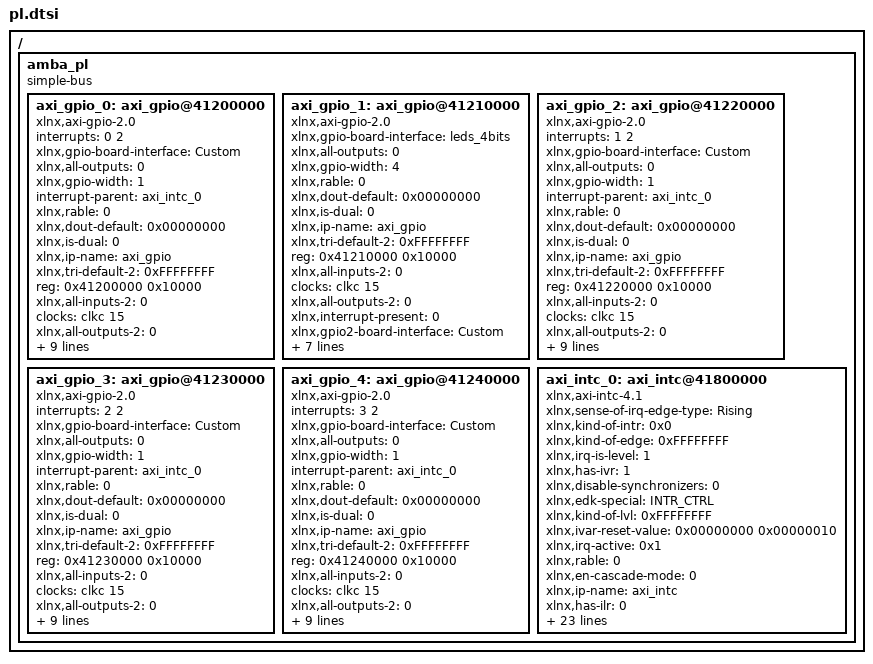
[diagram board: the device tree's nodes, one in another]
/ {
	amba_pl: amba_pl {
		ranges;
		compatible = "simple-bus";
		#address-cells = <1>;
		#size-cells = <1>;
		axi_gpio_0: axi_gpio@41200000 {
			#interrupt-cells = <2>;
			interrupts = < 0 2 >;
			xlnx,gpio-board-interface = "Custom";
			compatible = "xlnx,axi-gpio-2.0" , "xlnx,xps-gpio-1.00.a";
			xlnx,all-outputs = <0>;
			xlnx,gpio-width = <1>;
			interrupt-parent = <&axi_intc_0>;
			xlnx,rable = <0>;
			xlnx,dout-default = <0x00000000>;
			xlnx,is-dual = <0>;
			xlnx,ip-name = "axi_gpio";
			xlnx,tri-default-2 = <0xFFFFFFFF>;
			reg = <0x41200000 0x10000>;
			xlnx,all-inputs-2 = <0>;
			clocks = <&clkc 15>;
			xlnx,all-outputs-2 = <0>;
			xlnx,interrupt-present = <1>;
			xlnx,gpio2-board-interface = "Custom";
			xlnx,edk-iptype = "PERIPHERAL";
			xlnx,dout-default-2 = <0x00000000>;
			xlnx,gpio2-width = <32>;
			status = "okay";
			clock-names = "s_axi_aclk";
			interrupt-controller;
			interrupt-names = "ip2intc_irpt";
			xlnx,tri-default = <0xFFFFFFFF>;
			xlnx,name = "axi_gpio_0";
			xlnx,all-inputs = <1>;
		};
		axi_gpio_1: axi_gpio@41210000 {
			xlnx,gpio-board-interface = "leds_4bits";
			compatible = "xlnx,axi-gpio-2.0" , "xlnx,xps-gpio-1.00.a";
			xlnx,all-outputs = <0>;
			xlnx,gpio-width = <4>;
			xlnx,rable = <0>;
			xlnx,dout-default = <0x00000000>;
			xlnx,is-dual = <0>;
			xlnx,ip-name = "axi_gpio";
			xlnx,tri-default-2 = <0xFFFFFFFF>;
			reg = <0x41210000 0x10000>;
			xlnx,all-inputs-2 = <0>;
			clocks = <&clkc 15>;
			xlnx,all-outputs-2 = <0>;
			xlnx,interrupt-present = <0>;
			xlnx,gpio2-board-interface = "Custom";
			xlnx,edk-iptype = "PERIPHERAL";
			xlnx,dout-default-2 = <0x00000000>;
			xlnx,gpio2-width = <32>;
			status = "okay";
			clock-names = "s_axi_aclk";
			xlnx,use-board-flow;
			xlnx,tri-default = <0xFFFFFFFF>;
			xlnx,name = "axi_gpio_1";
			xlnx,all-inputs = <0>;
		};
		axi_gpio_2: axi_gpio@41220000 {
			#interrupt-cells = <2>;
			interrupts = < 1 2 >;
			xlnx,gpio-board-interface = "Custom";
			compatible = "xlnx,axi-gpio-2.0" , "xlnx,xps-gpio-1.00.a";
			xlnx,all-outputs = <0>;
			xlnx,gpio-width = <1>;
			interrupt-parent = <&axi_intc_0>;
			xlnx,rable = <0>;
			xlnx,dout-default = <0x00000000>;
			xlnx,is-dual = <0>;
			xlnx,ip-name = "axi_gpio";
			xlnx,tri-default-2 = <0xFFFFFFFF>;
			reg = <0x41220000 0x10000>;
			xlnx,all-inputs-2 = <0>;
			clocks = <&clkc 15>;
			xlnx,all-outputs-2 = <0>;
			xlnx,interrupt-present = <1>;
			xlnx,gpio2-board-interface = "Custom";
			xlnx,edk-iptype = "PERIPHERAL";
			xlnx,dout-default-2 = <0x00000000>;
			xlnx,gpio2-width = <32>;
			status = "okay";
			clock-names = "s_axi_aclk";
			interrupt-controller;
			interrupt-names = "ip2intc_irpt";
			xlnx,tri-default = <0xFFFFFFFF>;
			xlnx,name = "axi_gpio_2";
			xlnx,all-inputs = <1>;
		};
		axi_gpio_3: axi_gpio@41230000 {
			#interrupt-cells = <2>;
			interrupts = < 2 2 >;
			xlnx,gpio-board-interface = "Custom";
			compatible = "xlnx,axi-gpio-2.0" , "xlnx,xps-gpio-1.00.a";
			xlnx,all-outputs = <0>;
			xlnx,gpio-width = <1>;
			interrupt-parent = <&axi_intc_0>;
			xlnx,rable = <0>;
			xlnx,dout-default = <0x00000000>;
			xlnx,is-dual = <0>;
			xlnx,ip-name = "axi_gpio";
			xlnx,tri-default-2 = <0xFFFFFFFF>;
			reg = <0x41230000 0x10000>;
			xlnx,all-inputs-2 = <0>;
			clocks = <&clkc 15>;
			xlnx,all-outputs-2 = <0>;
			xlnx,interrupt-present = <1>;
			xlnx,gpio2-board-interface = "Custom";
			xlnx,edk-iptype = "PERIPHERAL";
			xlnx,dout-default-2 = <0x00000000>;
			xlnx,gpio2-width = <32>;
			status = "okay";
			clock-names = "s_axi_aclk";
			interrupt-controller;
			interrupt-names = "ip2intc_irpt";
			xlnx,tri-default = <0xFFFFFFFF>;
			xlnx,name = "axi_gpio_3";
			xlnx,all-inputs = <1>;
		};
		axi_gpio_4: axi_gpio@41240000 {
			#interrupt-cells = <2>;
			interrupts = < 3 2 >;
			xlnx,gpio-board-interface = "Custom";
			compatible = "xlnx,axi-gpio-2.0" , "xlnx,xps-gpio-1.00.a";
			xlnx,all-outputs = <0>;
			xlnx,gpio-width = <1>;
			interrupt-parent = <&axi_intc_0>;
			xlnx,rable = <0>;
			xlnx,dout-default = <0x00000000>;
			xlnx,is-dual = <0>;
			xlnx,ip-name = "axi_gpio";
			xlnx,tri-default-2 = <0xFFFFFFFF>;
			reg = <0x41240000 0x10000>;
			xlnx,all-inputs-2 = <0>;
			clocks = <&clkc 15>;
			xlnx,all-outputs-2 = <0>;
			xlnx,interrupt-present = <1>;
			xlnx,gpio2-board-interface = "Custom";
			xlnx,edk-iptype = "PERIPHERAL";
			xlnx,dout-default-2 = <0x00000000>;
			xlnx,gpio2-width = <32>;
			status = "okay";
			clock-names = "s_axi_aclk";
			interrupt-controller;
			interrupt-names = "ip2intc_irpt";
			xlnx,tri-default = <0xFFFFFFFF>;
			xlnx,name = "axi_gpio_4";
			xlnx,all-inputs = <1>;
		};
		axi_intc_0: axi_intc@41800000 {
			#interrupt-cells = <2>;
			xlnx,sense-of-irq-edge-type = "Rising";
			xlnx,kind-of-intr = <0x0>;
			xlnx,kind-of-edge = <0xFFFFFFFF>;
			xlnx,irq-is-level = <1>;
			xlnx,has-ivr = <1>;
			compatible = "xlnx,axi-intc-4.1" , "xlnx,xps-intc-1.00.a";
			xlnx,disable-synchronizers = <0>;
			xlnx,edk-special = "INTR_CTRL";
			xlnx,kind-of-lvl = <0xFFFFFFFF>;
			xlnx,ivar-reset-value = <0x00000000 0x00000010>;
			xlnx,irq-active = <0x1>;
			xlnx,rable = <0>;
			xlnx,en-cascade-mode = <0>;
			xlnx,ip-name = "axi_intc";
			xlnx,has-ilr = <0>;
			reg = <0x41800000 0x10000>;
			xlnx,addr-width = <0x20>;
			clocks = <&clkc 15>;
			xlnx,s-axi-aclk-freq-mhz = <100>;
			xlnx,num-sw-intr = <0>;
			xlnx,irq-connection = <0>;
			xlnx,num-intr-inputs = <0x4>;
			xlnx,has-sie = <1>;
			xlnx,has-cie = <1>;
			xlnx,enable-async = <0>;
			xlnx,num-sync-ff = <2>;
			xlnx,mb-clk-not-connected = <1>;
			xlnx,has-ipr = <1>;
			xlnx,edk-iptype = "PERIPHERAL";
			xlnx,sense-of-irq-level-type = "Active_High";
			xlnx,cascade-master = <0>;
			xlnx,processor-clk-freq-mhz = <100>;
			status = "okay";
			xlnx,is-fast = <0x0>;
			clock-names = "s_axi_aclk";
			xlnx,has-fast = <0>;
			xlnx,ivar-rst-val = <0x0000000000000010>;
			interrupt-controller;
			xlnx,async-intr = <0xFFFFFFF0>;
			xlnx,name = "axi_intc_0";
		};
	};
};
